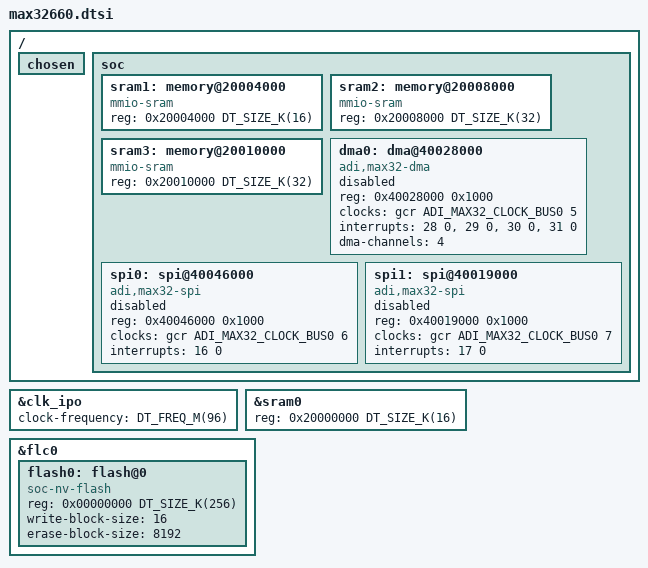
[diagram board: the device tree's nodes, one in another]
/*
 * Copyright (c) 2025 Analog Devices, Inc.
 *
 * SPDX-License-Identifier: Apache-2.0
 */

#include <arm/armv7-m.dtsi>
#include <adi/max32/max32xxx.dtsi>
#include <zephyr/dt-bindings/dma/max32660_dma.h>

&clk_ipo {
	clock-frequency = <DT_FREQ_M(96)>;
};

&sram0 {
	reg = <0x20000000 DT_SIZE_K(16)>;
};

/delete-node/ &clk_iso;
/delete-node/ &clk_ibro;
/delete-node/ &clk_erfo;
/delete-node/ &adc;
/delete-node/ &gpio1;
/delete-node/ &i2c2;
/delete-node/ &uart2;
/delete-node/ &timer3;
/delete-node/ &trng;
/delete-node/ &flash0;

&flc0 {
	flash0: flash@0{
		compatible = "soc-nv-flash";
		reg = <0x00000000 DT_SIZE_K(256)>;
		write-block-size = <16>;
		erase-block-size = <8192>;
	};
};

/* MAX32660 extra peripherals. */
/ {
	chosen {
		/delete-property/ zephyr,entropy;
	};

	soc {
		sram1: memory@20004000 {
			compatible = "mmio-sram";
			reg = <0x20004000 DT_SIZE_K(16)>;
		};

		sram2: memory@20008000 {
			compatible = "mmio-sram";
			reg = <0x20008000 DT_SIZE_K(32)>;
		};

		sram3: memory@20010000 {
			compatible = "mmio-sram";
			reg = <0x20010000 DT_SIZE_K(32)>;
		};

		dma0: dma@40028000 {
			compatible = "adi,max32-dma";
			reg = <0x40028000 0x1000>;
			clocks = <&gcr ADI_MAX32_CLOCK_BUS0 5>;
			interrupts = <28 0>, <29 0>, <30 0>, <31 0>;
			dma-channels = <4>;
			status = "disabled";
			#dma-cells = <2>;
		};

		spi0: spi@40046000 {
			compatible = "adi,max32-spi";
			reg = <0x40046000 0x1000>;
			#address-cells = <1>;
			#size-cells = <0>;
			clocks = <&gcr ADI_MAX32_CLOCK_BUS0 6>;
			interrupts = <16 0>;
			status = "disabled";
		};

		spi1: spi@40019000 {
			compatible = "adi,max32-spi";
			reg = <0x40019000 0x1000>;
			#address-cells = <1>;
			#size-cells = <0>;
			clocks = <&gcr ADI_MAX32_CLOCK_BUS0 7>;
			interrupts = <17 0>;
			status = "disabled";
		};
	};
};
